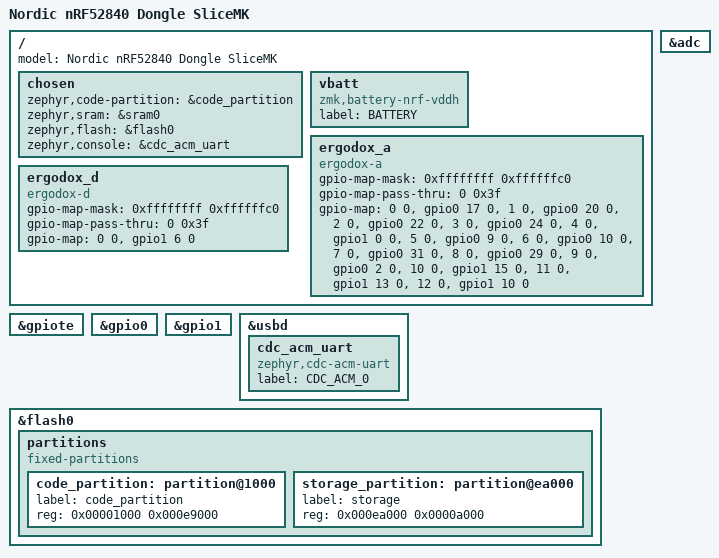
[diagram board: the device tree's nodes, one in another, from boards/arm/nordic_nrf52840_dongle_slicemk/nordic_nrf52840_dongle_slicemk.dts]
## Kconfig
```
# Copyright (c) 2020 The ZMK Contributors
# SPDX-License-Identifier: MIT

rsource "boards/Kconfig"
rsource "boards/shields/*/Kconfig.defconfig"
rsource "boards/shields/*/Kconfig.shield"

osource "$(ZMK_CONFIG)/boards/shields/*/Kconfig.defconfig"
osource "$(ZMK_CONFIG)/boards/shields/*/Kconfig.shield"

mainmenu "ZMK Firmware"

menu "ZMK"

menu "Basic Keyboard Setup"

config ZMK_KEYBOARD_NAME
    string "Keyboard Name"

config USB_DEVICE_PRODUCT
    default ZMK_KEYBOARD_NAME

config BT_DEVICE_NAME
    default ZMK_KEYBOARD_NAME

config USB_DEVICE_VID
    default 0x1D50

config USB_DEVICE_PID
    default 0x615E

config USB_DEVICE_MANUFACTURER
    default "ZMK Project"

config BT_DIS_PNP_VID
    default 0x1D50

config BT_DIS_PNP_PID
    default 0x615E

config BT_DIS_MODEL
    default ZMK_KEYBOARD_NAME

config BT_DIS_MANUF
    default "ZMK Project"

menu "HID"

choice ZMK_HID_REPORT_TYPE
    prompt "HID Report Type"

config ZMK_HID_REPORT_TYPE_HKRO
    bool "#-Key Roll Over (HKRO) HID Report"
    help
      Enable # key roll over for HID report. This selection is "boot keyboard" compatible
      but limits the total number of possible keys to report as held to #.

config ZMK_HID_REPORT_TYPE_NKRO
    bool "Full N-Key Roll Over (NKRO) HID Report"
    help
      Enable full N-Key Roll Over for HID output. This selection will prevent the keyboard
      from working with some BIOS/UEFI versions that only support "boot keyboard" support.
      This option also prevents using some infrequently used higher range HID usages.

endchoice

if ZMK_HID_REPORT_TYPE_HKRO

config ZMK_HID_KEYBOARD_REPORT_SIZE
    int "# Keyboard Keys Reportable"
    default 6

endif

config ZMK_HID_CONSUMER_REPORT_SIZE
    int "# Consumer Keys Reportable"
    default 6


choice ZMK_HID_CONSUMER_REPORT_USAGES
    prompt "HID Report Type"

config ZMK_HID_CONSUMER_REPORT_USAGES_FULL
    bool "Full Consumer HID Usage Support"
    help
      Enable full Consumer usage ID values to be sent to hosts. Allows for less
      frequently used usages, but has compatibability issues with some host OSes.

config ZMK_HID_CONSUMER_REPORT_USAGES_BASIC
    bool "Basic Consumer HID Usage Support"
    help
      Enable Consumer usage ID values up to "Playback Speed - Slow" to be sent to
      hosts. Allows for broader compatibability with more host OSes.

endchoice

menu "Output Types"

config ZMK_USB
    bool "USB"
    select USB
    select USB_DEVICE_STACK
    select USB_DEVICE_HID

if ZMK_USB

config USB_NUMOF_EP_WRITE_RETRIES
    default 10

config USB_HID_POLL_INTERVAL_MS
    default 1

#ZMK_USB
endif

menuconfig ZMK_BLE
    bool "BLE (HID over GATT)"
    select BT
    select BT_SMP
    select BT_SMP_SC_PAIR_ONLY
    select BT_SMP_APP_PAIRING_ACCEPT
    select BT_PERIPHERAL
    select BT_DIS
    select BT_SETTINGS
    select SETTINGS
    imply ZMK_BATTERY_REPORTING

if ZMK_BLE

# BT_TINYCRYPT_ECC is required for BT_SMP_SC_PAIR_ONLY when using HCI
config BT_TINYCRYPT_ECC
    default y if BT_HCI && !BT_CTLR

choice BT_LL_SW_LLCP_IMPL
    default BT_LL_SW_LLCP_LEGACY

endchoice

config SYSTEM_WORKQUEUE_STACK_SIZE
    default 4096 if SOC_RP2040
    default 2048

config ZMK_BLE_THREAD_STACK_SIZE
    int "BLE notify thread stack size"
    default 768

config ZMK_BLE_THREAD_PRIORITY
    int "BLE notify thread priority"
    default 5

config ZMK_BLE_KEYBOARD_REPORT_QUEUE_SIZE
    int "Max number of keyboard HID reports to queue for sending over BLE"
    default 20

config ZMK_BLE_CONSUMER_REPORT_QUEUE_SIZE
    int "Max number of consumer HID reports to queue for sending over BLE"
    default 5

config ZMK_BLE_CLEAR_BONDS_ON_START
    bool "Configuration that clears all bond information from the keyboard on startup."
    default n

# HID GATT notifications sent this way are *not* picked up by Linux, and possibly others.
config BT_GATT_NOTIFY_MULTIPLE
    default n

config BT_GATT_AUTO_SEC_REQ
    default n

config BT_DEVICE_APPEARANCE
    default 961

config ZMK_BLE_PASSKEY_ENTRY
    bool "Require passkey entry on the keyboard to complete pairing"
    default n
    select RING_BUFFER

config BT_PERIPHERAL_PREF_MIN_INT
    default 6

config BT_PERIPHERAL_PREF_MAX_INT
    default 12

config BT_PERIPHERAL_PREF_LATENCY
    default 30

config BT_PERIPHERAL_PREF_TIMEOUT
    default 400

#ZMK_BLE
endif

#Output Types
endmenu

# HID
endmenu

rsource "src/split/Kconfig"

#Basic Keyboard Setup
endmenu

menu "Display/LED Options"

rsource "src/display/Kconfig"

menuconfig ZMK_RGB_UNDERGLOW
    bool "RGB Adressable LED Underglow"
    select LED_STRIP

if ZMK_RGB_UNDERGLOW

# This default value cuts down on tons of excess .conf files, if you're using GPIO, manually disable this
config SPI
    default y

config ZMK_RGB_UNDERGLOW_EXT_POWER
    bool "RGB underglow toggling also controls external power"
    default y

config ZMK_RGB_UNDERGLOW_BRT_MIN
    int "RGB underglow minimum brightness in percent"
    range 0 100
    default 0

config ZMK_RGB_UNDERGLOW_BRT_MAX
    int "RGB underglow maximum brightness in percent"
    range ZMK_RGB_UNDERGLOW_BRT_MIN 100
    default 100

config ZMK_RGB_UNDERGLOW_HUE_STEP
    int "RGB underglow hue step in degrees"
    range 0 359
    default 10

config ZMK_RGB_UNDERGLOW_SAT_STEP
    int "RGB underglow saturation step in percent"
    range 0 100
    default 10

config ZMK_RGB_UNDERGLOW_BRT_STEP
    int "RGB underglow brightness step in percent"
    range 0 100
    default 10

config ZMK_RGB_UNDERGLOW_HUE_START
    int "RGB underglow start hue value in degrees"
    range 0 359
    default 0

config ZMK_RGB_UNDERGLOW_SAT_START
    int "RGB underglow start saturations value in percent"
    range 0 100
    default 100

config ZMK_RGB_UNDERGLOW_BRT_START
    int "RGB underglow start brightness value in percent"
    range ZMK_RGB_UNDERGLOW_BRT_MIN ZMK_RGB_UNDERGLOW_BRT_MAX
    default ZMK_RGB_UNDERGLOW_BRT_MAX

config ZMK_RGB_UNDERGLOW_SPD_START
    int "RGB underglow start animation speed value"
    range 1 5
    default 3

config ZMK_RGB_UNDERGLOW_EFF_START
    int "RGB underglow start effect int value related to the effect enum list"
    range 0 3
    default 0

config ZMK_RGB_UNDERGLOW_ON_START
    bool "RGB underglow starts on by default"
    default y

config ZMK_RGB_UNDERGLOW_AUTO_OFF_IDLE
    bool "Turn off RGB underglow when keyboard goes into idle state"

config ZMK_RGB_UNDERGLOW_AUTO_OFF_USB
    bool "Turn off RGB underglow when USB is disconnected"
    depends on USB_DEVICE_STACK

#ZMK_RGB_UNDERGLOW
endif

menuconfig ZMK_BACKLIGHT
    bool "LED backlight"
    select LED

if ZMK_BACKLIGHT

config ZMK_BACKLIGHT_BRT_STEP
    int "Brightness step in percent"
    range 1 100
    default 20

config ZMK_BACKLIGHT_BRT_START
    int "Default brightness in percent"
    range 1 100
    default 40

config ZMK_BACKLIGHT_ON_START
    bool "Default backlight state"
    default y

config ZMK_BACKLIGHT_AUTO_OFF_IDLE
    bool "Turn off backlight when keyboard goes into idle state"

config ZMK_BACKLIGHT_AUTO_OFF_USB
    bool "Turn off backlight when USB is disconnected"

#ZMK_BACKLIGHT
endif

#Display/LED Options
endmenu

menu "Power Management"

config ZMK_BATTERY_REPORTING
    bool "Battery level detection/reporting"
    default n
    select SENSOR
    select BT_BAS if ZMK_BLE

config ZMK_IDLE_TIMEOUT
    int "Milliseconds of inactivity before entering idle state (OLED shutoff, etc)"
    default 30000

config ZMK_SLEEP
    bool "Enable deep sleep support"
    imply USB

if ZMK_SLEEP

config PM_DEVICE
    default y

config ZMK_IDLE_SLEEP_TIMEOUT
    int "Milliseconds of inactivity before entering deep sleep"
    default 900000

#ZMK_SLEEP
endif

config ZMK_EXT_POWER
    bool "Enable support to control external power output"
    default y

#Power Management
endmenu

menu "Combo options"

config ZMK_COMBO_MAX_PRESSED_COMBOS
    int "Maximum number of currently pressed combos"
    default 4

config ZMK_COMBO_MAX_COMBOS_PER_KEY
    int "Maximum number of combos per key"
    default 5

config ZMK_COMBO_MAX_KEYS_PER_COMBO
    int "Maximum number of keys per combo"
    default 4

config ZMK_COMBO_MAX_LAYERS_PER_COMBO
    int "Maximum number of layers specified per combo"
    default 4

#Combo options
endmenu

menu "Behavior Options"

config ZMK_BEHAVIORS_QUEUE_SIZE
    int "Maximum number of behaviors to allow queueing from a macro or other complex behavior"
    default 64

rsource "Kconfig.behaviors"

config ZMK_MACRO_DEFAULT_WAIT_MS
    int "Default time to wait (in milliseconds) before triggering the next behavior in macros"
    default 15

config ZMK_MACRO_DEFAULT_TAP_MS
    int "Default time to wait (in milliseconds) between the press and release events of a tapped behavior in macros"
    default 30

endmenu

menu "Advanced"

menu "Initialization Priorities"

if USB_DEVICE_STACK

config ZMK_USB_INIT_PRIORITY
    int "USB Init Priority"
    default 50

#USB
endif

if ZMK_BLE || ZMK_SPLIT_BLE

config ZMK_BLE_INIT_PRIORITY
    int "BLE Init Priority"
    default 50

#ZMK_BLE || ZMK_SPLIT_BLE
endif

#Initialization Priorities
endmenu

menu "KSCAN Settings"

config ZMK_KSCAN_EVENT_QUEUE_SIZE
    int "Size of the event queue for KSCAN events to buffer events"
    default 4

#KSCAN Settings
endmenu

menu "Logging"

config ZMK_LOGGING_MINIMAL
    bool "Suppress all ZMK debug log messages"
    default false

if !ZMK_LOGGING_MINIMAL

config ZMK_LOG_LEVEL
    default 4

endif

config ZMK_USB_LOGGING
    bool "Enable USB CDC ACM logging to help debug"
    select LOG
    select USB
    select USB_DEVICE_STACK
    select USB_CDC_ACM
    select SERIAL
    select CONSOLE
    select UART_INTERRUPT_DRIVEN
    select UART_LINE_CTRL
    select UART_CONSOLE
    select USB_UART_CONSOLE

if ZMK_USB_LOGGING

# Suppress USB CDC ACM "ring buffer full" info messages. ZMK default "off" is
# broken in Zephyr 3.2 (but fine in Zephyr 3.4). See
# https://github.com/zmkfirmware/zmk/issues/1832.
choice USB_CDC_ACM_LOG_LEVEL_CHOICE
    default USB_CDC_ACM_LOG_LEVEL_WRN
endchoice

choice USB_DRIVER_LOG_LEVEL_CHOICE
    default USB_DRIVER_LOG_LEVEL_OFF
endchoice

# We do this to avoid log loop where logging to USB generates more log messages.

config USB_CDC_ACM_RINGBUF_SIZE
    default 1024

config LOG_PROCESS_THREAD_STARTUP_DELAY_MS
    default 1000

#ZMK_USB_LOGGING
endif

config ZMK_RTT_LOGGING
    bool "Enable RTT logging to help debug"
    select LOG
    select DEBUG
    select ASSERT
    select USE_SEGGER_RTT
    select CONSOLE
    select RTT_CONSOLE

if ZMK_RTT_LOGGING

config SEGGER_RTT_BUFFER_SIZE_UP
    default 8192

#ZMK_RTT_LOGGING
endif

if ZMK_USB_LOGGING || ZMK_RTT_LOGGING

config LOG_BUFFER_SIZE
    default 8192

config LOG_PROCESS_THREAD_SLEEP_MS
    default 100

#ZMK_USB_LOGGING || ZMK_RTT_LOGGING
endif

#Logging
endmenu

if SETTINGS

config ZMK_SETTINGS_SAVE_DEBOUNCE
    int "Milliseconds to debounce settings saves"
    default 60000

#SETTINGS
endif

config ZMK_BATTERY_REPORT_INTERVAL
    depends on ZMK_BLE
    int "Battery level report interval in seconds"
    default 60

#Advanced
endmenu

#ZMK
endmenu

config HEAP_MEM_POOL_SIZE
    default 8192

config KERNEL_BIN_NAME
    default "zmk"

config REBOOT
    default y

config USB_DEVICE_STACK
    default y if HAS_HW_NRF_USBD

config ZMK_WPM
    bool "Calculate WPM"
    default n

config ZMK_KEYMAP_SENSORS
    bool "Enable Keymap Sensors support"
    default y
    depends on DT_HAS_ZMK_KEYMAP_SENSORS_ENABLED
    select SENSOR

if ZMK_KEYMAP_SENSORS

config ZMK_KEYMAP_SENSORS_DEFAULT_TRIGGERS_PER_ROTATION
    int "Default triggers per rotation"
    help
      Unless overridden for a sensor in the board/shield/devicetree, this value
      determines how many times to trigger the bound behavior per full rotation.
      For tactile encoders with detents, this usually should match the number of
      detents per rotation of the encoder.
    default 20

endif # ZMK_KEYMAP_SENSORS

choice CBPRINTF_IMPLEMENTATION
    default CBPRINTF_NANO

endchoice

module = ZMK
module-str = zmk
source "subsys/logging/Kconfig.template.log_config"

source "Kconfig.zephyr"
```

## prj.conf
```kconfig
CONFIG_ZMK_BEHAVIORS_QUEUE_SIZE=512

# Increase stacks to reduce possibility of an overflow.
CONFIG_MAIN_STACK_SIZE=2048
CONFIG_SYSTEM_WORKQUEUE_STACK_SIZE=2048
CONFIG_ZMK_BLE_THREAD_STACK_SIZE=2048
CONFIG_ZMK_SPLIT_BLE_CENTRAL_SPLIT_RUN_STACK_SIZE=2048
CONFIG_ISR_STACK_SIZE=2048
```

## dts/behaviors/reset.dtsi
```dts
/*
 * Copyright (c) 2020 The ZMK Contributors
 *
 * SPDX-License-Identifier: MIT
 */

#include <dt-bindings/zmk/reset.h>

/ {
    behaviors {
        sys_reset: behavior_reset {
            compatible = "zmk,behavior-reset";
            label = "SYSRESET";
            #binding-cells = <0>;
        };

        bootloader: behavior_reset_dfu {
            compatible = "zmk,behavior-reset";
            label = "BOOTLOAD";
            type = <RST_UF2>;
            #binding-cells = <0>;
        };

		sys_off: behavior_reset_sysoff {
			compatible = "zmk,behavior-reset";
			label = "SYSOFF";
			type = <RST_SYSOFF>;
			#binding-cells = <0>;
		};
	};
};
```

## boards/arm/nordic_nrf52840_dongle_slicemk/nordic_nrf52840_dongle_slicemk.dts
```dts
/dts-v1/;
#include <nordic/nrf52840_qiaa.dtsi>

/ {
	model = "Nordic nRF52840 Dongle SliceMK";

	chosen {
		zephyr,code-partition = &code_partition;
		zephyr,sram = &sram0;
		zephyr,flash = &flash0;
		zephyr,console = &cdc_acm_uart;
	};

	// There is no battery so make pretend with VDDHDIV5.
	vbatt {
		compatible = "zmk,battery-nrf-vddh";
		label = "BATTERY";
	};

	// Define GPIOs for 202202 keyboard matrix.
	ergodox_a: ergodox_a {
		compatible = "ergodox-a";
		#gpio-cells = <2>;
		gpio-map-mask = <0xffffffff 0xffffffc0>;
		gpio-map-pass-thru = <0 0x3f>;
		gpio-map
			= <0 0 &gpio0 17 0>
			, <1 0 &gpio0 20 0>
			, <2 0 &gpio0 22 0>
			, <3 0 &gpio0 24 0>
			, <4 0 &gpio1 0 0>
			, <5 0 &gpio0 9 0>
			, <6 0 &gpio0 10 0>
			, <7 0 &gpio0 31 0>
			, <8 0 &gpio0 29 0>
			, <9 0 &gpio0 2 0>
			, <10 0 &gpio1 15 0>
			, <11 0 &gpio1 13 0>
			, <12 0 &gpio1 10 0>
			;
	};

	// Define user button.
	ergodox_d: ergodox_d {
		compatible = "ergodox-d";
		#gpio-cells = <2>;
		gpio-map-mask = <0xffffffff 0xffffffc0>;
		gpio-map-pass-thru = <0 0x3f>;
		gpio-map = <0 0 &gpio1 6 0>;
	};
};

&adc {
	status = "okay";
};

&gpiote {
	status = "okay";
};

&gpio0 {
	status = "okay";
};

&gpio1 {
	status = "okay";
};

&usbd {
	status = "okay";
	cdc_acm_uart: cdc_acm_uart {
		compatible = "zephyr,cdc-acm-uart";
		label = "CDC_ACM_0";
	};
};

&flash0 {
	partitions {
		compatible = "fixed-partitions";
		#address-cells = <1>;
		#size-cells = <1>;

		// Application starts at 0x1000 after the MBR.
		code_partition: partition@1000 {
			label = "code_partition";
			reg = <0x00001000 0x000e9000>;
		};

		// Define storage partition before the bootloader, which starts at
		// 0xf4000. The storage partition has been 10 pages since Adafruit
		// bootloader version 0.6.0.
		storage_partition: partition@ea000 {
			label = "storage";
			reg = <0x000ea000 0x0000a000>;
		};
	};
};
```

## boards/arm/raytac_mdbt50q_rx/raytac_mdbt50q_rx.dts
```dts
/dts-v1/;
#include <nordic/nrf52840_qiaa.dtsi>

/ {
	model = "Raytac MDBT50Q-RX";

	chosen {
		zephyr,code-partition = &code_partition;
		zephyr,sram = &sram0;
		zephyr,flash = &flash0;
		zephyr,console = &cdc_acm_uart;
	};

	// Define user button.
	ergodox_d: ergodox_d {
		compatible = "ergodox-d";
		#gpio-cells = <2>;
		gpio-map-mask = <0xffffffff 0xffffffc0>;
		gpio-map-pass-thru = <0 0x3f>;
		gpio-map = <0 0 &gpio0 15 0>;
	};
};

&adc {
	status = "okay";
};

&gpiote {
	status = "okay";
};

&gpio0 {
	status = "okay";
};

&gpio1 {
	status = "okay";
};

&usbd {
	status = "okay";
	cdc_acm_uart: cdc_acm_uart {
		compatible = "zephyr,cdc-acm-uart";
		label = "CDC_ACM_0";
	};
};

&flash0 {
	partitions {
		compatible = "fixed-partitions";
		#address-cells = <1>;
		#size-cells = <1>;

		// Application starts at 0x1000 after the MBR.
		code_partition: partition@1000 {
			label = "code_partition";
			reg = <0x00001000 0x000ec000>;
		};

		// Define storage partition before the bootloader, which starts at
		// 0xf4000. Only 7 pages is allocated for storage since that's the
		// default on the older Adafruit bootloader that these dongles are
		// preloaded with.
		storage_partition: partition@ed000 {
			label = "storage";
			reg = <0x000ed000 0x00007000>;
		};
	};
};
```

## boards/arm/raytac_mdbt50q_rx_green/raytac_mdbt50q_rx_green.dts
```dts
/dts-v1/;
#include <nordic/nrf52833_qiaa.dtsi>

/ {
	model = "Raytac MDBT50Q-RX Green";

	chosen {
		zephyr,code-partition = &code_partition;
		zephyr,sram = &sram0;
		zephyr,flash = &flash0;
		zephyr,console = &cdc_acm_uart;
	};

	// Define user button.
	ergodox_d: ergodox_d {
		compatible = "ergodox-d";
		#gpio-cells = <2>;
		gpio-map-mask = <0xffffffff 0xffffffc0>;
		gpio-map-pass-thru = <0 0x3f>;
		gpio-map = <0 0 &gpio0 15 0>;
	};
};

&adc {
	status = "okay";
};

&gpiote {
	status = "okay";
};

&gpio0 {
	status = "okay";
};

&gpio1 {
	status = "okay";
};

&usbd {
	status = "okay";
	cdc_acm_uart: cdc_acm_uart {
		compatible = "zephyr,cdc-acm-uart";
		label = "CDC_ACM_0";
	};
};

&flash0 {
	partitions {
		compatible = "fixed-partitions";
		#address-cells = <1>;
		#size-cells = <1>;

		code_partition: partition@1000 {
			label = "code_partition";
			reg = <0x00001000 0x0006c000>;
		};

		storage_partition: partition@6d000 {
			label = "storage";
			reg = <0x0006d000 0x00007000>;
		};
	};
};
```

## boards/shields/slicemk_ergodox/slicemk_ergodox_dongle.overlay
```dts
#include "slicemk_ergodox.dtsi"

/ {
	kscan0: kscan {
		compatible = "zmk,kscan-gpio-direct";
		label = "KSCAN";
		input-gpios = <&ergodox_d 0 (GPIO_ACTIVE_LOW | GPIO_PULL_UP)>;
	};
};
```

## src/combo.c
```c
/*
 * Copyright (c) 2020 The ZMK Contributors
 *
 * SPDX-License-Identifier: MIT
 */

#define DT_DRV_COMPAT zmk_combos

#include <zephyr/device.h>
#include <zephyr/logging/log.h>
#include <zephyr/sys/dlist.h>
#include <zephyr/kernel.h>

#include <drivers/behavior.h>

#include <zmk/behavior.h>
#include <zmk/event_manager.h>
#include <zmk/events/position_state_changed.h>
#include <zmk/hid.h>
#include <zmk/matrix.h>
#include <zmk/keymap.h>
#include <zmk/virtual_key_position.h>

LOG_MODULE_DECLARE(zmk, CONFIG_ZMK_LOG_LEVEL);

#if DT_HAS_COMPAT_STATUS_OKAY(DT_DRV_COMPAT)

struct combo_cfg {
    int32_t key_positions[CONFIG_ZMK_COMBO_MAX_KEYS_PER_COMBO];
    int32_t key_position_len;
    int32_t timeout_ms;
    // if slow release is set, the combo releases when any key in slow_release_positions is released
    // or all keys are released. otherwise, the combo releases when the first key is released.
    bool slow_release;
    int32_t slow_release_positions[CONFIG_ZMK_COMBO_MAX_KEYS_PER_COMBO];
    int32_t slow_release_positions_len;
    int8_t layers[CONFIG_ZMK_COMBO_MAX_LAYERS_PER_COMBO];
    int32_t layers_len;
    // the virtual key position is a key position outside the range used by the keyboard.
    // it is necessary so hold-taps can uniquely identify a behavior.
    int32_t virtual_key_position;
    int32_t behaviors_len;
    struct zmk_behavior_binding behaviors[];
};

struct active_combo {
    struct combo_cfg *combo;
    // key_positions_pressed is filled with key_positions when the combo is pressed.
    // The keys are removed from this array when they are released.
    // Once this array is empty, the behavior is released.
    const zmk_event_t *key_positions_pressed[CONFIG_ZMK_COMBO_MAX_KEYS_PER_COMBO];
    // keep track if the behavior has already been released (used for slow release)
    bool behavior_released;
};

struct combo_candidate {
    struct combo_cfg *combo;
    // the time after which this behavior should be removed from candidates.
    // by keeping track of when the candidate should be cleared there is no
    // possibility of accidental releases.
    int64_t timeout_at;
};

// set of keys pressed
const zmk_event_t *pressed_keys[CONFIG_ZMK_COMBO_MAX_KEYS_PER_COMBO] = {NULL};
// the set of candidate combos based on the currently pressed_keys
struct combo_candidate candidates[CONFIG_ZMK_COMBO_MAX_COMBOS_PER_KEY];
// the last candidate that was completely pressed
struct combo_cfg *fully_pressed_combo = NULL;
// a lookup dict that maps a key position to all combos on that position
struct combo_cfg *combo_lookup[ZMK_KEYMAP_LEN][CONFIG_ZMK_COMBO_MAX_COMBOS_PER_KEY] = {NULL};
// combos that have been activated and still have (some) keys pressed
// this array is always contiguous from 0.
struct active_combo active_combos[CONFIG_ZMK_COMBO_MAX_PRESSED_COMBOS] = {NULL};
int active_combo_count = 0;

struct k_work_delayable timeout_task;
int64_t timeout_task_timeout_at;

// Store the combo key pointer in the combos array, one pointer for each key position
// The combos are sorted shortest-first, then by virtual-key-position.
static int initialize_combo(struct combo_cfg *new_combo) {
    for (int i = 0; i < new_combo->key_position_len; i++) {
        int32_t position = new_combo->key_positions[i];
        if (position >= ZMK_KEYMAP_LEN) {
            LOG_ERR("Unable to initialize combo, key position %d does not exist", position);
            return -EINVAL;
        }

        struct combo_cfg *insert_combo = new_combo;
        bool set = false;
        for (int j = 0; j < CONFIG_ZMK_COMBO_MAX_COMBOS_PER_KEY; j++) {
            struct combo_cfg *combo_at_j = combo_lookup[position][j];
            if (combo_at_j == NULL) {
                combo_lookup[position][j] = insert_combo;
                set = true;
                break;
            }
            if (combo_at_j->key_position_len < insert_combo->key_position_len ||
                (combo_at_j->key_position_len == insert_combo->key_position_len &&
                 combo_at_j->virtual_key_position < insert_combo->virtual_key_position)) {
                continue;
            }
            // put insert_combo in this spot, move all other combos up.
            combo_lookup[position][j] = insert_combo;
            insert_combo = combo_at_j;
        }
        if (!set) {
            LOG_ERR("Too many combos for key position %d, CONFIG_ZMK_COMBO_MAX_COMBOS_PER_KEY %d.",
                    position, CONFIG_ZMK_COMBO_MAX_COMBOS_PER_KEY);
            return -ENOMEM;
        }
    }
    return 0;
}

static bool combo_active_on_layer(struct combo_cfg *combo, uint8_t layer) {
    if (combo->layers[0] == -1) {
        // -1 in the first layer position is global layer scope
        return true;
    }
    for (int j = 0; j < combo->layers_len; j++) {
        if (combo->layers[j] == layer) {
            return true;
        }
    }
    return false;
}

static int setup_candidates_for_first_keypress(int32_t position, int64_t timestamp) {
    int number_of_combo_candidates = 0;
    uint8_t highest_active_layer = zmk_keymap_highest_layer_active();
    for (int i = 0; i < CONFIG_ZMK_COMBO_MAX_COMBOS_PER_KEY; i++) {
        struct combo_cfg *combo = combo_lookup[position][i];
        if (combo == NULL) {
            return number_of_combo_candidates;
        }
        if (combo_active_on_layer(combo, highest_active_layer)) {
            candidates[number_of_combo_candidates].combo = combo;
            candidates[number_of_combo_candidates].timeout_at = timestamp + combo->timeout_ms;
            number_of_combo_candidates++;
        }
        // LOG_DBG("combo timeout %d %d %d", position, i, candidates[i].timeout_at);
    }
    return number_of_combo_candidates;
}

static int filter_candidates(int32_t position) {
    // this code iterates over candidates and the lookup together to filter in O(n)
    // assuming they are both sorted on key_position_len, virtal_key_position
    int matches = 0, lookup_idx = 0, candidate_idx = 0;
    while (lookup_idx < CONFIG_ZMK_COMBO_MAX_COMBOS_PER_KEY &&
           candidate_idx < CONFIG_ZMK_COMBO_MAX_COMBOS_PER_KEY) {
        struct combo_cfg *candidate = candidates[candidate_idx].combo;
        struct combo_cfg *lookup = combo_lookup[position][lookup_idx];
        if (candidate == NULL || lookup == NULL) {
            break;
        }
        if (candidate->virtual_key_position == lookup->virtual_key_position) {
            candidates[matches] = candidates[candidate_idx];
            matches++;
            candidate_idx++;
            lookup_idx++;
        } else if (candidate->key_position_len > lookup->key_position_len) {
            lookup_idx++;
        } else if (candidate->key_position_len < lookup->key_position_len) {
            candidate_idx++;
        } else if (candidate->virtual_key_position > lookup->virtual_key_position) {
            lookup_idx++;
        } else if (candidate->virtual_key_position < lookup->virtual_key_position) {
            candidate_idx++;
        }
    }
    // clear unmatched candidates
    for (int i = matches; i < CONFIG_ZMK_COMBO_MAX_COMBOS_PER_KEY; i++) {
        candidates[i].combo = NULL;
    }
    // LOG_DBG("combo matches after filter %d", matches);
    return matches;
}

static int64_t first_candidate_timeout() {
    int64_t first_timeout = LONG_MAX;
    for (int i = 0; i < CONFIG_ZMK_COMBO_MAX_COMBOS_PER_KEY; i++) {
        if (candidates[i].combo == NULL) {
            break;
        }
        if (candidates[i].timeout_at < first_timeout) {
            first_timeout = candidates[i].timeout_at;
        }
    }
    return first_timeout;
}

static inline bool candidate_is_completely_pressed(struct combo_cfg *candidate) {
    // this code assumes set(pressed_keys) <= set(candidate->key_positions)
    // this invariant is enforced by filter_candidates
    // since events may have been reraised after clearing one or more slots at
    // the start of pressed_keys (see: release_pressed_keys), we have to check
    // that each key needed to trigger the combo was pressed, not just the last.
    for (int i = 0; i < candidate->key_position_len; i++) {
        if (pressed_keys[i] == NULL) {
            return false;
        }
    }
    return true;
}

static int cleanup();

static int filter_timed_out_candidates(int64_t timestamp) {
    int num_candidates = 0;
    for (int i = 0; i < CONFIG_ZMK_COMBO_MAX_COMBOS_PER_KEY; i++) {
        struct combo_candidate *candidate = &candidates[i];
        if (candidate->combo == NULL) {
            break;
        }
        if (candidate->timeout_at > timestamp) {
            // reorder candidates so they're contiguous
            candidates[num_candidates].combo = candidate->combo;
            candidates[num_candidates].timeout_at = candidate->timeout_at;
            num_candidates++;
        } else {
            candidate->combo = NULL;
        }
    }
    return num_candidates;
}

static int clear_candidates() {
    for (int i = 0; i < CONFIG_ZMK_COMBO_MAX_COMBOS_PER_KEY; i++) {
        if (candidates[i].combo == NULL) {
            return i;
        }
        candidates[i].combo = NULL;
    }
    return CONFIG_ZMK_COMBO_MAX_COMBOS_PER_KEY;
}

static int capture_pressed_key(const zmk_event_t *ev) {
    for (int i = 0; i < CONFIG_ZMK_COMBO_MAX_KEYS_PER_COMBO; i++) {
        if (pressed_keys[i] != NULL) {
            continue;
        }
        pressed_keys[i] = ev;
        return ZMK_EV_EVENT_CAPTURED;
    }
    return 0;
}

const struct zmk_listener zmk_listener_combo;

static int release_pressed_keys() {
    for (int i = 0; i < CONFIG_ZMK_COMBO_MAX_KEYS_PER_COMBO; i++) {
        const zmk_event_t *captured_event = pressed_keys[i];
        if (pressed_keys[i] == NULL) {
            return i;
        }
        pressed_keys[i] = NULL;
        if (i == 0) {
            LOG_DBG("combo: releasing position event %d",
                    as_zmk_position_state_changed(captured_event)->position);
            ZMK_EVENT_RAISE_AFTER(captured_event, combo);
        } else {
            // reprocess events (see tests/combo/fully-overlapping-combos-3 for why this is needed)
            LOG_DBG("combo: reraising position event %d",
                    as_zmk_position_state_changed(captured_event)->position);
            ZMK_EVENT_RAISE(captured_event);
        }
    }
    return CONFIG_ZMK_COMBO_MAX_KEYS_PER_COMBO;
}

static inline int process_behavior(int32_t position, int32_t timestamp,
                                   struct zmk_behavior_binding *behavior, bool pressed) {
    struct zmk_behavior_binding_event event = {
        .position = position,
        .timestamp = timestamp,
    };

    if (pressed) {
        return behavior_keymap_binding_pressed(behavior, event);
    } else {
        return behavior_keymap_binding_released(behavior, event);
    }
}

static inline int process_combo_behavior(struct combo_cfg *combo, int32_t timestamp, bool pressed) {
    return process_behavior(combo->virtual_key_position, timestamp, &combo->behaviors[0], pressed);
}

// press or release the behavior at the given position, used for partial holds
static inline int process_position(int32_t position, int32_t timestamp, const zmk_event_t *ev,
                                   bool pressed) {
    const struct zmk_position_state_changed *pos_ev;
    if ((pos_ev = as_zmk_position_state_changed(ev)) != NULL) {
        return zmk_keymap_position_state_changed(pos_ev->source, position, pressed, timestamp);
    }
    return -ENOTSUP;
}

static void move_pressed_keys_to_active_combo(struct active_combo *active_combo) {
    int combo_length = active_combo->combo->key_position_len;
    for (int i = 0; i < combo_length; i++) {
        active_combo->key_positions_pressed[i] = pressed_keys[i];
        pressed_keys[i] = NULL;
    }
    // move any other pressed keys up
    for (int i = 0; i + combo_length < CONFIG_ZMK_COMBO_MAX_KEYS_PER_COMBO; i++) {
        if (pressed_keys[i + combo_length] == NULL) {
            return;
        }
        pressed_keys[i] = pressed_keys[i + combo_length];
        pressed_keys[i + combo_length] = NULL;
    }
}

static struct active_combo *store_active_combo(struct combo_cfg *combo) {
    for (int i = 0; i < CONFIG_ZMK_COMBO_MAX_PRESSED_COMBOS; i++) {
        if (active_combos[i].combo == NULL) {
            active_combos[i].combo = combo;
            active_combos[i].behavior_released = false;
            active_combo_count++;
            return &active_combos[i];
        }
    }
    LOG_ERR("Unable to store combo; already %d active. Increase "
            "CONFIG_ZMK_COMBO_MAX_PRESSED_COMBOS",
            CONFIG_ZMK_COMBO_MAX_PRESSED_COMBOS);
    return NULL;
}

static void activate_combo(struct combo_cfg *combo) {
    struct active_combo *active_combo = store_active_combo(combo);
    if (active_combo == NULL) {
        // unable to store combo
        release_pressed_keys();
        return;
    }
    move_pressed_keys_to_active_combo(active_combo);
    process_combo_behavior(
        combo, as_zmk_position_state_changed(active_combo->key_positions_pressed[0])->timestamp,
        true);
}

static void deactivate_combo(int active_combo_index) {
    active_combo_count--;
    if (active_combo_index != active_combo_count) {
        memcpy(&active_combos[active_combo_index], &active_combos[active_combo_count],
               sizeof(struct active_combo));
    }
    active_combos[active_combo_count].combo = NULL;
    active_combos[active_combo_count] = (struct active_combo){0};
}

#define ZM_IS_NODE_MATCH(a, b) (strcmp(a, b) == 0)
#define PARTIAL_HOLD_POSITION DT_PROP(DT_INST(0, zmk_combo_partial_hold_position), label)
#define IS_PARTIAL_HOLD_POSITION(dev) ZM_IS_NODE_MATCH(dev, PARTIAL_HOLD_POSITION)

/* returns true if a key was released. */
static bool release_combo_key(int32_t position, int64_t timestamp, const zmk_event_t *ev) {
    for (int combo_idx = 0; combo_idx < active_combo_count; combo_idx++) {
        struct active_combo *active_combo = &active_combos[combo_idx];

        bool key_released = false;
        bool all_keys_pressed = true;
        bool all_keys_released = true;
        for (int i = 0; i < active_combo->combo->key_position_len; i++) {
            if (active_combo->key_positions_pressed[i] == NULL) {
                all_keys_pressed = false;
            } else if (as_zmk_position_state_changed(active_combo->key_positions_pressed[i])
                           ->position != position) {
                all_keys_released = false;
            } else { // not null and position matches
                ZMK_EVENT_FREE(active_combo->key_positions_pressed[i]);
                active_combo->key_positions_pressed[i] = NULL;
                key_released = true;
            }
        }

        if (key_released) {
            // slow release
            if (!active_combo->combo->slow_release && all_keys_pressed) {
                // if slow release is not enabled, release the behavior
                process_combo_behavior(active_combo->combo, timestamp, false);
            } else if (active_combo->combo->slow_release && !active_combo->behavior_released) {
                // if slow release is enabled and the behavior has not yet been released
                if (all_keys_released) {
                    // if all keys are released, release the behavior
                    process_combo_behavior(active_combo->combo, timestamp, false);
                    active_combo->behavior_released = true;
                } else {
                    // if the key being released is a slow release key, release the behavior,
                    // otherwise ignore
                    for (int i = 0; i < active_combo->combo->slow_release_positions_len; i++) {
                        if (active_combo->combo->slow_release_positions[i] == position) {
                            process_combo_behavior(active_combo->combo, timestamp, false);
                            active_combo->behavior_released = true;
                        }
                    }
                }
            }

            // partial holds
            for (int i = 1; i < active_combo->combo->behaviors_len; i++) {
                // loop through every behavior except the first. If the behavior is a partial hold
                // position, process it. If the next behavior is also a behavior, press that
                // behavior instead of the key at the position.
                struct zmk_behavior_binding *binding = &active_combo->combo->behaviors[i];
                // if the behavior is not a partial hold position, skip it
                if (!IS_PARTIAL_HOLD_POSITION(binding->behavior_dev)) {
                    continue;
                }
                int32_t partial_hold_position = binding->param1;
                // if the next behavior is a behavior (not a partial hold position)
                bool has_explicit_behavior =
                    i == active_combo->combo->behaviors_len - 1
                        ? false
                        : !IS_PARTIAL_HOLD_POSITION(
                              active_combo->combo->behaviors[i + 1].behavior_dev);

                // if all keys were pressed, press all other partial hold keys that are still held
                if (all_keys_pressed) {
                    // except the one that was released
                    if (partial_hold_position != position) {
                        // either press the position, or press the behavior
                        if (has_explicit_behavior) {
                            process_behavior(position, timestamp,
                                             &active_combo->combo->behaviors[i + 1], true);
                        } else {
                            process_position(partial_hold_position, timestamp, ev, true);
                        }
                    }
                } else {
                    // now release any partial hold keys that are released
                    if (partial_hold_position == position) {
                        // either release the position, or release the behavior
                        if (has_explicit_behavior) {
                            process_behavior(position, timestamp,
                                             &active_combo->combo->behaviors[i + 1], false);
                        } else {
                            process_position(partial_hold_position, timestamp, ev, false);
                        }
                    }
                }
            }

            if (all_keys_released) {
                deactivate_combo(combo_idx);
            }
            return true;
        }
    }
    return false;
}

static int cleanup() {
    k_work_cancel_delayable(&timeout_task);
    clear_candidates();
    if (fully_pressed_combo != NULL) {
        activate_combo(fully_pressed_combo);
        fully_pressed_combo = NULL;
    }
    return release_pressed_keys();
}

static void update_timeout_task() {
    int64_t first_timeout = first_candidate_timeout();
    if (timeout_task_timeout_at == first_timeout) {
        return;
    }
    if (first_timeout == LLONG_MAX) {
        timeout_task_timeout_at = 0;
        k_work_cancel_delayable(&timeout_task);
        return;
    }
    if (k_work_schedule(&timeout_task, K_MSEC(first_timeout - k_uptime_get())) >= 0) {
        timeout_task_timeout_at = first_timeout;
    }
}

static int position_state_down(const zmk_event_t *ev, struct zmk_position_state_changed *data) {
    int num_candidates;
    if (candidates[0].combo == NULL) {
        num_candidates = setup_candidates_for_first_keypress(data->position, data->timestamp);
        if (num_candidates == 0) {
            return 0;
        }
    } else {
        filter_timed_out_candidates(data->timestamp);
        num_candidates = filter_candidates(data->position);
    }
    update_timeout_task();

    struct combo_cfg *candidate_combo = candidates[0].combo;
    LOG_DBG("combo: capturing position event %d", data->position);
    int ret = capture_pressed_key(ev);
    switch (num_candidates) {
    case 0:
        cleanup();
        return ret;
    case 1:
        if (candidate_is_completely_pressed(candidate_combo)) {
            fully_pressed_combo = candidate_combo;
            cleanup();
        }
        return ret;
    default:
        if (candidate_is_completely_pressed(candidate_combo)) {
            fully_pressed_combo = candidate_combo;
        }
        return ret;
    }
}

static int position_state_up(const zmk_event_t *ev, struct zmk_position_state_changed *data) {
    int released_keys = cleanup();
    if (release_combo_key(data->position, data->timestamp, ev)) {
        return ZMK_EV_EVENT_HANDLED;
    }
    if (released_keys > 1) {
        // The second and further key down events are re-raised. To preserve
        // correct order for e.g. hold-taps, reraise the key up event too.
        ZMK_EVENT_RAISE(ev);
        return ZMK_EV_EVENT_CAPTURED;
    }
    return 0;
}

static void combo_timeout_handler(struct k_work *item) {
    if (timeout_task_timeout_at == 0 || k_uptime_get() < timeout_task_timeout_at) {
        // timer was cancelled or rescheduled.
        return;
    }
    if (filter_timed_out_candidates(timeout_task_timeout_at) < 2) {
        cleanup();
    }
    update_timeout_task();
}

static int position_state_changed_listener(const zmk_event_t *ev) {
    struct zmk_position_state_changed *data = as_zmk_position_state_changed(ev);
    if (data == NULL) {
        return 0;
    }

    if (data->state) { // keydown
        return position_state_down(ev, data);
    } else { // keyup
        return position_state_up(ev, data);
    }
}

ZMK_LISTENER(combo, position_state_changed_listener);
ZMK_SUBSCRIPTION(combo, zmk_position_state_changed);

#define BINDING_WITH_COMMA(idx, drv_inst) ZMK_KEYMAP_EXTRACT_BINDING(idx, drv_inst)

#define TRANSFORMED_BEHAVIORS(n)                                                                   \
    { LISTIFY(DT_PROP_LEN(n, bindings), BINDING_WITH_COMMA, (, ), n) }

#define COMBO_INST(n)                                                                              \
    static struct combo_cfg combo_config_##n = {                                                   \
        .timeout_ms = DT_PROP(n, timeout_ms),                                                      \
        .key_positions = DT_PROP(n, key_positions),                                                \
        .key_position_len = DT_PROP_LEN(n, key_positions),                                         \
        .slow_release = DT_PROP(n, slow_release),                                                  \
        .slow_release_positions = DT_PROP(n, slow_release_positions),                              \
        .slow_release_positions_len = DT_PROP_LEN(n, slow_release_positions),                      \
        .layers = DT_PROP(n, layers),                                                              \
        .layers_len = DT_PROP_LEN(n, layers),                                                      \
        .virtual_key_position = ZMK_VIRTUAL_KEY_POSITION_COMBO(__COUNTER__),                       \
        .behaviors = TRANSFORMED_BEHAVIORS(n),                                                     \
        .behaviors_len = DT_PROP_LEN(n, bindings),                                                 \
    };

#define INITIALIZE_COMBO(n) initialize_combo(&combo_config_##n);

DT_INST_FOREACH_CHILD(0, COMBO_INST)

static int combo_init() {
    k_work_init_delayable(&timeout_task, combo_timeout_handler);
    DT_INST_FOREACH_CHILD(0, INITIALIZE_COMBO);
    return 0;
}

SYS_INIT(combo_init, APPLICATION, CONFIG_KERNEL_INIT_PRIORITY_DEFAULT);

#endif
```
